# psoc4100tp register map
Vendor: Infineon Technologies; Series: PSOC4100Tp; File version: 1.0
CPU: CM0PLUS r0p1, little endian, no MPU, no FPU, VTOR, 2 interrupt priority bits, 23 interrupts
Registers are 32-bit, read-write, reset 0x0 unless marked. A register's access mark holds for its fields unless they carry their own. Offsets are from the block's base; [hi:lo] are bit positions; lines under a group give offsets from that group; {n}, {i} and the like mark numbered series; 'fields as' and 'values as' point back to an identical list; <NAME> marks a mode.

## GPIO — GPIO port control/configuration
Base 0x40040000
{0x0+0x100*i} PRT[{i}] (i=0..6) group — GPIO port registers
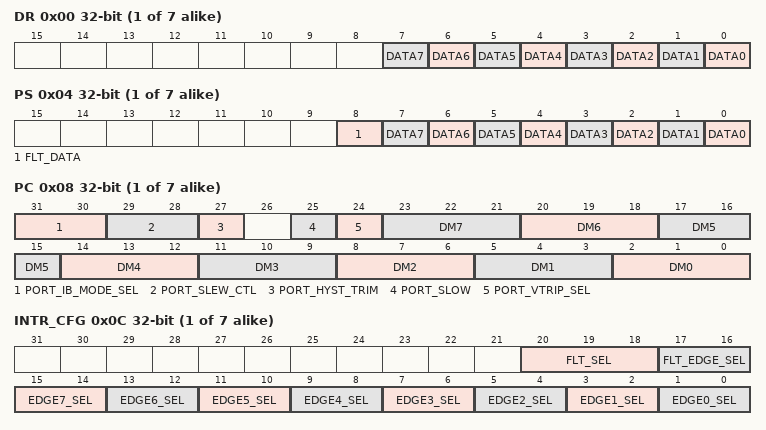
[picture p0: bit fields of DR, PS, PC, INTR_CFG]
  0x00 DR — Port output data register
    [n] DATA{n} (n=0..7) — IO pad {n} output data.
  0x04 PS ro — Port IO pad state register
    [8] FLT_DATA — Reads of this register return the logical state of the filtered pin.
    [n] DATA{n} (n=1..7) — IO pad {n} state.
    [0] DATA0 — IO pad 0 state: 1: Logic high, if the pin voltage is above the input buffer threshold, logic high. 0: Logic low, if the pin voltage is below that threshold, logic low. If the drive mode for the pin is set to high Z Analog, the pin state will read 0 independent of the voltage on the pin.
  0x08 PC — Port configuration register
    [31:30] PORT_IB_MODE_SEL
    [29:28] PORT_SLEW_CTL — This field is used to vary slew rate in I2C mode. It comes into picture only when slow=1 and DM=4 ( strong pull down, open drain). Following modes are supported and the corresponding fall time specs are mentioned:
      0=HS mode (100pf < Cb < 400pF, 1.71<VDDD<5.5, Vext>3.0) FS mode (10pf<Cb<400pf,1.71<VDDD<5.5) (20-160ns); 1=HS mode (Cb<100pf,1.71<VDDD<5.5,Vext>2.8,F=1.7MHz) (10-80ns) FS+ Mode (Vext>2.8,1.71<VDDD<5.5) (20-120ns); 2=HS mode (100pf<Cb<400pf, 1.71<VDDD<5.5,Vext<3.3) (20-160ns); 3=HS mode (Cb<100pf,1.71<VDDD<5.5,Vext<=2.8,F=1.7MHz) (10-80ns) FS+ mode (Vext<=2.8,1.71<VDDD<5.5) (20-120ns)
    [27] PORT_HYST_TRIM
    [25] PORT_SLOW
    [24] PORT_VTRIP_SEL
    [3n+2:3n] DM{n} (n=1..7)
    [2:0] DM0
      0=OFF (Mode 0 (analog mode): Output buffer off (high Z). Input buffer off.); 1=INPUT (Mode 1: Output buffer off (high Z). Input buffer on.); 2=0_PU (Mode 2: Strong pull down ('0'), weak/resistive pull up (PU). Input buffer on. For GPIOV1P2_I2C, Strong pull down only.); 3=PD_1 (Mode 3: Weak/resistive pull down (PD), strong pull up ('1'). Input buffer on. For GPIOV1P2_I2C: Weak pull down only.); 4=0_Z (Mode 4: Strong pull down ('0'), open drain (pull up off). Input buffer on. For GPIOV1P2_I2C, Strong pull down only.); 5=Z_1 (Mode 5: Open drain (pull down off), strong pull up ('1'). Input buffer on. Illegal for GPIOV1P2_I2C); 6=Mode 6: Strong pull down ('0'), strong pull up ('1'). Input buffer on. For GPIOV1P2_I2C, Strong pull down only.; 7=PD_PU (Mode 7: Weak/resistive pull down (PD), weak/resistive pull up (PU). Input buffer on. For GPIOV1P2_I2C: Weak pull down only.)
  0x0C INTR_CFG — Port interrupt configuration register
    [20:18] FLT_SEL — Selects which pin is routed through the 50ns glitch filter to provide a glitch-safe interrupt.
    [17:16] FLT_EDGE_SEL — Same for the glitch filtered pin (selected by FLT_SEL).
      0=DISABLE (Disabled); 1=RISING (Rising edge); 2=FALLING (Falling edge); 3=BOTH (Both rising and falling edges)
    [2n+1:2n] EDGE{n}_SEL (n=1..7) — Sets which edge will trigger an IRQ for IO pad {n}.
    [1:0] EDGE0_SEL — Sets which edge will trigger an IRQ for IO pad 0.
      values as FLT_EDGE_SEL
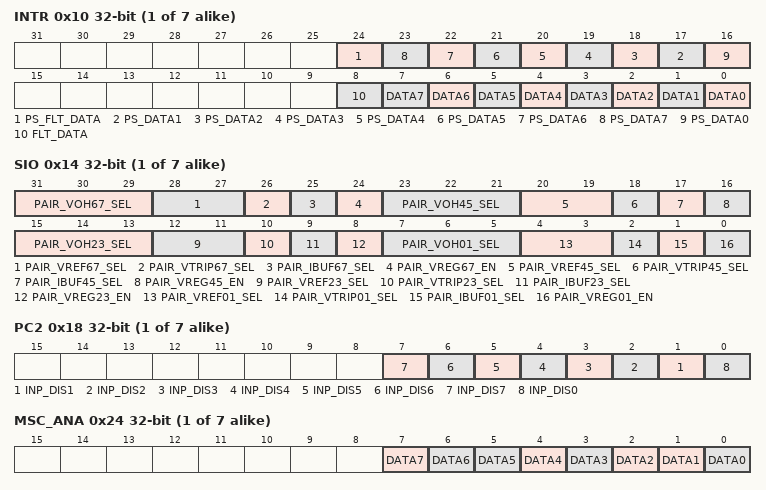
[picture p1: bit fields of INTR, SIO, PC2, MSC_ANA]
  0x10 INTR — Port interrupt status register
    [24] PS_FLT_DATA ro — This is a duplicate of the contents of the PS register, provided here to allow reading of both pin state and interrupt state of the port in a single read operation.
    [n+16] PS_DATA{n} ro (n=1..7)
    [16] PS_DATA0 ro — `
    [8] FLT_DATA write-1-clears — Deglitched interrupt pending (selected by FLT_SEL).
    [n] DATA{n} write-1-clears (n=0..7) — Interrupt pending on IO pad {n}. Firmware writes 1 to clear the interrupt.
  0x14 SIO — Port SIO configuration register
    [31:29] PAIR_VOH67_SEL
    [28:27] PAIR_VREF67_SEL
    [26] PAIR_VTRIP67_SEL
    [25] PAIR_IBUF67_SEL
    [24] PAIR_VREG67_EN
    [23:21] PAIR_VOH45_SEL
    [20:19] PAIR_VREF45_SEL
    [18] PAIR_VTRIP45_SEL
    [17] PAIR_IBUF45_SEL
    [16] PAIR_VREG45_EN
    [15:13] PAIR_VOH23_SEL
    [12:11] PAIR_VREF23_SEL
    [10] PAIR_VTRIP23_SEL
    [9] PAIR_IBUF23_SEL
    [8] PAIR_VREG23_EN
    [7:5] PAIR_VOH01_SEL — Selects regulated Voh output level and trip point of input buffer for a specific SIO pin pair. Voh depends on the selected Vref voltage (see table in PAIR_VREF_01SEL description for details). 0: Voh = 1*vref 1: Voh = 1.25*vref 2: Voh = 1.49*vref 3: Voh = 1.67*vref 4: Voh = 2.08*vref 5: Voh = 2.5*vref 6: Voh = 2.78*vref 7: Voh = 4.16*vref Note: The upper value on Voh is limited to Vddio - 400mV
    [4:3] PAIR_VREF01_SEL — Selects reference voltage Vref for trip-point of input buffer and reference for VOH regulator: 0: Vref = 1.2V (input buffers use vddio as Vref) 1: Vref = 1.2V 2: Vref = AMUXBUS_A 3: Vref = AMUXBUS_B
    [2] PAIR_VTRIP01_SEL — In single ended input buffer mode (PAIR_IBUF01_SEL = '0'): VTRIP_SEL=0: input buffer functions as a CMOS input buffer. VTRIP_SEL=1: input buffer functions as a LVTTL input buffer. In differential input buffer mode (PAIR_IBUF01_SEL = '1'): PAIR_VREF01_SEL=00: a) PAIR_VTRIP01_SEL=0 -> Trip point=50 percent of vddio b) PAIR_VTRIP01_SEL=1 -> Trip point=40 percent of vddio PAIR_VREF01_SEL=01/10/11: a) PAIR_VTRIP01_SEL=0 -> Trip point=50 percent of Voh (see table in PAIR_VOH01_SEL for details) b) PAIR_VTRIP01_SEL=1 -> Trip point=Vref (see table in PAIR_VREF01_SEL for details)
    [1] PAIR_IBUF01_SEL — Selects input buffer mode: 0: singled ended input buffer with a threshold controlled by PAIR_VTRIP01_SEL 1: differential input buffer, see table in PAIR_VTRIP01_SEL description for details
    [0] PAIR_VREG01_EN — Selects output buffer mode: 0: unregulated output buffer 1: regulated output buffer The regulated output configuration is selected ONLY if the dm<2:0> bits set a strong pull up configuration (Modes 3, 5, or 6). Weak pull up modes pull to VDDIO.
  0x18 PC2 — Port configuration register 2
    [n] INP_DIS{n} (n=1..7) — Disables the input buffer for IO pad {n}.
    [0] INP_DIS0 — Disables the input buffer for IO pad 0 independent of the port control drive mode (PC.DM). This bit should be set when analog signals are present on the pin and PC.DM != 0 is required to use the output driver.
  0x24 MSC_ANA — Port MSCLP AMUX enable
    [7] DATA7 — IO pad 7 MSC_ANA_EN
    [6] DATA6 — IO pad 6 MSC_ANA_EN.
    [n] DATA{n} (n=2..5) — IO pad {n} MSC_ANA_EN
    [1] DATA1 — IO pad 1 MSC_ANA_EN.
    [0] DATA0 — IO pad 0 MSC_ANA_EN
  0x40 DR_SET — Port output data set register
    [7:0] DATA — IO pad i: '0': Output state DR.DATA[i] not affected. '1': Output state DR.DATA[i] set to '1'.
  0x44 DR_CLR — Port output data clear register
    [7:0] DATA — IO pad i: '0': Output state DR.DATA[i] not affected. '1': Output state DR.DATA[i] set to '0'.
  0x48 DR_INV — Port output data invert register
    [7:0] DATA — IO pad i: '0': Output state DR.DATA[i] not affected. '1': Output state DR.DATA[i] inverted ('0' => '1', '1' => '0').
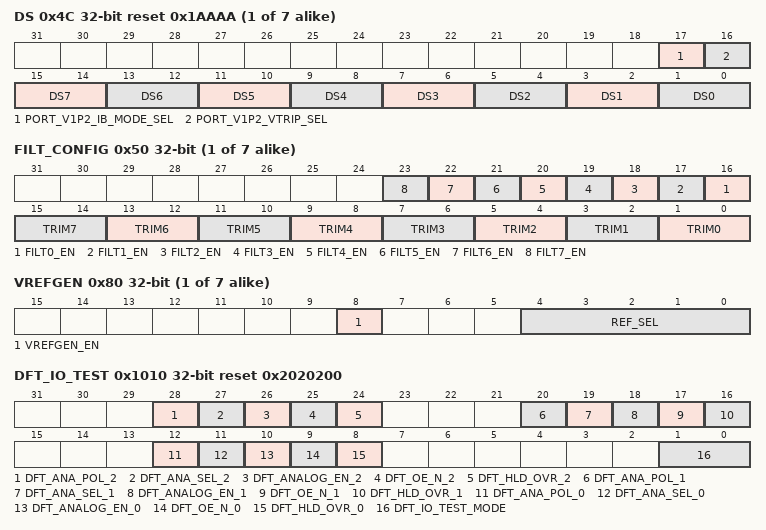
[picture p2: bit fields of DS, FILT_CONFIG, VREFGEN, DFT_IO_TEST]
  0x4C DS reset 0x1AAAA — Port drive strength register
    [17] PORT_V1P2_IB_MODE_SEL
    [16] PORT_V1P2_VTRIP_SEL
    [2n+1:2n] DS{n} (n=1..7)
    [1:0] DS0
      0=1 ma drive nominal - changes with external R/C loading and I2C speed (Standard, Fast, Fast+); 1=2 ma drive nominal - changes with external R/C loading and I2C speed (Standard, Fast, Fast+); 2=4 ma drive nominal - changes with external R/C loading and I2C speed (Standard, Fast, Fast+); 3=8 ma drive nominal - changes with external R/C loading and I2C speed (Standard, Fast, Fast+)
  0x50 FILT_CONFIG — IO filter config register
    [n+16] FILT{n}_EN (n=0..7), [2n+1:2n] TRIM{n} (n=0..7)
  0x80 VREFGEN — Reference generator configuration register
    [8] VREFGEN_EN — Reference generator enable: '0': Disabled. '1': Enabled.
    [4:0] REF_SEL — Reference selection. A reference Voltage vinref is created using a Voltage vddio: '0': vinref = (0 * 13 + 184)/600 * vddio = 184/600 * vddio. '1': vinref = (1 * 13 + 184)/600 * vddio = 197/600 * vddio. '2': vinref = (2 * 13 + 184)/600 * vddio = 210/600 * vddio. ... '31': vinref = (31 * 13 + 184)/600 * vddio = 587/600 * vddio.
0x1000 INTR_CAUSE ro — Interrupt port cause register
  [31:0] PORT_INT — Each IO port has an associated bit field in this register. The bit field reflects the IO port's interrupt line (bit field i reflects 'interrupts_gpio[i]' for IO port i). The register is used when the system uses a shared/combined interrupt line 'interrupt_gpio'. The SW ISR reads the register to determine which IO port(s) is responsible for the shared/combined interrupt line 'interrupt_gpio'. Once, the IO port(s) is determined, the IO port's INTR register is read to determine the IO pad(s) in the IO port that caused the interrupt.
0x1010 DFT_IO_TEST reset 0x2020200 — IO SELF TEST control register for DfT purposes only
  [28] DFT_ANA_POL_2 — 'analog_pol' DfT control for IO cells depending on DFT_IO_TEST_MODE as given below. TEST_ADFT: Connects to 'analog_pol' of all IO cells other than ADFT-0/1. TEST_ANA: Connects to 'analog_pol' of all IO cells other than IO_TEST_0/1. TEST_GEN: Connects to 'analog_pol' of all IO cells.
  [27] DFT_ANA_SEL_2 — 'analog_sel' DfT control for IO cells depending on DFT_IO_TEST_MODE as given below. TEST_ADFT: Connects to 'analog_sel' of all IO cells other than ADFT-0/1. TEST_ANA: Connects to 'analog_sel' of all IO cells other than IO_TEST_0/1. TEST_GEN: Connects to 'analog_sel' of all IO cells.
  [26] DFT_ANALOG_EN_2 — 'analog_en' DfT control for IO cells depending on DFT_IO_TEST_MODE as given below. TEST_ADFT: Connects to 'analog_en' of all IO cells other than ADFT-0/1. TEST_ANA: DFT_ANALOG_EN_2 && DM[0] connects to 'analog_en' of all IO cells other than IO_TEST_0/1. TEST_GEN: Connects to 'analog_en' of all IO cells
  [25] DFT_OE_N_2 — 'oe_n' DfT control for IO cells depending on DFT_IO_TEST_MODE as given below. TEST_ADFT: Connects to 'oe_n' of all IO cells other than ADFT-0/1. TEST_ANA: Connects to 'oe_n' of all IO cells other than IO_TEST_0/1. TEST_GEN: Connects to 'oe_n' of all IO cells
  [24] DFT_HLD_OVR_2 — 'hld_ovr' DfT control for IO cells depending on DFT_IO_TEST_MODE as given below. TEST_ADFT: Connects to 'hld_ovr' of all IO cells other than ADFT-0/1 . TEST_ANA: Connects to 'hld_ovr' of all IO cells other than IO_TEST_0/1. TEST_GEN: Connects to 'hld_ovr' of all IO cells.
  [20] DFT_ANA_POL_1 — 'analog_pol' DfT control for IO cells depending on DFT_IO_TEST_MODE as given below. TEST_ADFT: Connects to 'analog_pol' of the ADFT-1 assigned IO cell. TEST_ANA: Connects to 'analog_pol' of the IO_TEST_1 assigned IO cell. TEST_GEN: not used.
  [19] DFT_ANA_SEL_1 — 'analog_sel' DfT control for IO cells depending on DFT_IO_TEST_MODE as given below. TEST_ADFT: Connects to 'analog_sel' of the ADFT-1 assigned IO cell. TEST_ANA: Connects to 'analog_sel' of the IO_TEST_1 assigned IO cell. TEST_GEN: not used.
  [18] DFT_ANALOG_EN_1 — 'analog_en' DfT control for IO cells depending on DFT_IO_TEST_MODE as given below. TEST_ADFT: Connects to 'analog_en' of the ADFT-1 assigned IO cell. TEST_ANA: Connects to 'analog_en' of the IO_TEST_1 assigned IO cell. TEST_GEN: not used.
  [17] DFT_OE_N_1 — 'oe_n' DfT control for IO cells depending on DFT_IO_TEST_MODE as given below. TEST_ADFT: Connects to 'oe_n' of the ADFT-1 assigned IO cell. TEST_ANA: Connects to 'oe_n' of the IO_TEST_1 assigned IO cell. TEST_GEN: not used.
  [16] DFT_HLD_OVR_1 — 'hld_ovr' DfT control for IO cells depending on DFT_IO_TEST_MODE as given below. TEST_ADFT: Connects to 'hld_ovr' of the ADFT-1 assigned IO cell. TEST_ANA: Connects to 'hld_ovr' of the IO_TEST_1 assigned IO cell. TEST_GEN: not used.
  [12] DFT_ANA_POL_0 — 'analog_pol' DfT control for IO cells depending on DFT_IO_TEST_MODE as given below. TEST_ADFT: Connects to 'analog_pol' of the ADFT-0 assigned IO cell. TEST_ANA: Connects to 'analog_pol' of the IO_TEST_0 assigned IO cell. TEST_GEN: not used.
  [11] DFT_ANA_SEL_0 — 'analog_sel' DfT control for IO cells depending on DFT_IO_TEST_MODE as given below. TEST_ADFT: Connects to 'analog_sel' of the ADFT-0 assigned IO cell. TEST_ANA: Connects to 'analog_sel' of the IO_TEST_0 assigned IO cell. TEST_GEN: not used.
  [10] DFT_ANALOG_EN_0 — 'analog_en' DfT control for IO cells depending on DFT_IO_TEST_MODE as given below. TEST_ADFT: Connects to 'analog_en' of the ADFT-0 assigned IO cell. TEST_ANA: Connects to 'analog_en' of the IO_TEST_0 assigned IO cell. TEST_GEN: not used.
  [9] DFT_OE_N_0 — 'oe_n' DfT control for IO cells depending on DFT_IO_TEST_MODE as given below. TEST_ADFT: Connects to 'oe_n' of the ADFT-0 assigned IO cell. TEST_ANA: Connects to 'oe_n' of the IO_TEST_0 assigned IO cell. TEST_GEN: not used.
  [8] DFT_HLD_OVR_0 — 'hld_ovr' DfT control for IO cells depending on DFT_IO_TEST_MODE as given below. TEST_ADFT: Connects to 'hld_ovr' of the ADFT-0 assigned IO cell. TEST_ANA: Connects to 'hld_ovr' of the IO_TEST_0 assigned IO cell. TEST_GEN: not used.
  [1:0] DFT_IO_TEST_MODE — DfT IO SELF TEST mode:
    0=OFF (Functional mode: disables the DfT IO SELF TEST; none of the 'DFT_*' control signals from this register control the IO cells.); 1=TEST_ADFT (select this mode during ADFT testing to control 'hld_ovr/oe_n/ analog_sel/ analog_pol/ analog_en' signals of IO cells as below: the ADFT-0 assigned IO cell connects to: DFT_*_0; the ADFT-1 assigned IO cell connects to: DFT_*_1; ...); 2=TEST_ANA (select this mode for testing analog switches to control 'hld_ovr/oe_n/analog_en/analog_sel/analog_pol' signals of IO cells as below: the IO_TEST_0 assigned IO cell connects to: DFT_*_0; the IO_TEST_1 assigned IO cell connects to: DFT_*_1;...); 3=TEST_GEN (select this mode for generic testing to control 'hld_ovr/oe_n/analog_en/analog_sel/analog_pol' signals of IO cells as below: All IO cells connect to: DFT_*_2;)
0x1020 GPIOV1P2_DET ro — GPIOV1P2 Detect output
  [0] DET — Indicates HI when VDDIO is in 1.8V range, and LOW when VDDIO is in 1.2V range.

## Notices in the file
(c) 2016-2026, Infineon Technologies AG or an affiliate of
Infineon Technologies AG.
SPDX-License-Identifier: Apache-2.0
Licensed under the Apache License, Version 2.0 (the "License");
you may not use this file except in compliance with the License.
You may obtain a copy of the License at
http://www.apache.org/licenses/LICENSE-2.0
Unless required by applicable law or agreed to in writing, software
distributed under the License is distributed on an "AS IS" BASIS,
WITHOUT WARRANTIES OR CONDITIONS OF ANY KIND, either express or implied.
See the License for the specific language governing permissions and
limitations under the License.
